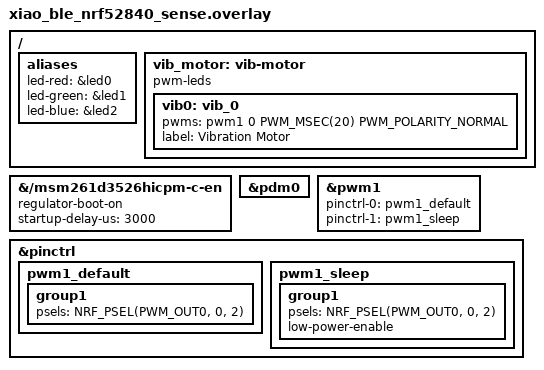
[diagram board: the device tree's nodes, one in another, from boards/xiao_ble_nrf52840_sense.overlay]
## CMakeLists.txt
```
cmake_minimum_required(VERSION 3.20.0)
find_package(Zephyr REQUIRED HINTS $ENV{ZEPHYR_BASE})
project(inside_voice)

target_sources(app PRIVATE
    src/main.c
    src/app/config.c
    src/app/monitor.c
    src/app/data_cache.c
    src/audio/pdm_capture.c
    src/audio/sound_level.c
    src/ble/ble_manager.c
    src/ble/config_service.c
    src/feedback/led.c
    src/feedback/vibration.c
)
```

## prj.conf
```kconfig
# Bluetooth
CONFIG_BT=y
CONFIG_BT_PERIPHERAL=y
CONFIG_BT_DEVICE_NAME="InsideVoice"
CONFIG_BT_DEVICE_APPEARANCE=0
CONFIG_BT_MAX_CONN=1
CONFIG_BT_GATT_DYNAMIC_DB=y

# Audio (PDM/DMIC)
CONFIG_AUDIO=y
CONFIG_AUDIO_DMIC=y

# PWM (vibration motor)
CONFIG_PWM=y

# GPIO (LEDs)
CONFIG_GPIO=y
CONFIG_LED=y

# Persistent settings (NVS)
CONFIG_NVS=y
CONFIG_SETTINGS=y
CONFIG_SETTINGS_NVS=y
CONFIG_FLASH=y
CONFIG_FLASH_MAP=y
CONFIG_FLASH_PAGE_LAYOUT=y

# USB CDC ACM console
CONFIG_USB_DEVICE_STACK=y
CONFIG_USB_CDC_ACM=y
CONFIG_SERIAL=y
CONFIG_CONSOLE=y
CONFIG_UART_CONSOLE=y
CONFIG_UART_LINE_CTRL=y

# Logging
CONFIG_LOG=y
CONFIG_LOG_DEFAULT_LEVEL=3

# Power (enable DC-DC converter for battery life)
CONFIG_BOARD_ENABLE_DCDC=y

# System
CONFIG_HEAP_MEM_POOL_SIZE=4096
CONFIG_MAIN_STACK_SIZE=4096
```

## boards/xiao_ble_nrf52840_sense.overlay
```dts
/ {
	aliases {
		led-red = &led0;
		led-green = &led1;
		led-blue = &led2;
	};

	vib_motor: vib-motor {
		compatible = "pwm-leds";
		status = "okay";

		vib0: vib_0 {
			pwms = <&pwm1 0 PWM_MSEC(20) PWM_POLARITY_NORMAL>;
			label = "Vibration Motor";
		};
	};
};

/* Enable PDM mic power regulator (GPIO P1.10) at boot */
&{/msm261d3526hicpm-c-en} {
	regulator-boot-on;
	startup-delay-us = <3000>;
};

&pdm0 {
	status = "okay";
};

&pwm1 {
	status = "okay";
	pinctrl-0 = <&pwm1_default>;
	pinctrl-1 = <&pwm1_sleep>;
	pinctrl-names = "default", "sleep";
};

&pinctrl {
	pwm1_default: pwm1_default {
		group1 {
			psels = <NRF_PSEL(PWM_OUT0, 0, 2)>;
		};
	};

	pwm1_sleep: pwm1_sleep {
		group1 {
			psels = <NRF_PSEL(PWM_OUT0, 0, 2)>;
			low-power-enable;
		};
	};
};
```

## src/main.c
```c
#include <zephyr/kernel.h>
#include <zephyr/logging/log.h>

#include "app/config.h"
#include "app/monitor.h"
#include "audio/pdm_capture.h"
#include "ble/ble_manager.h"
#include "ble/config_service.h"
#include "feedback/led.h"
#include "feedback/vibration.h"

LOG_MODULE_REGISTER(main, LOG_LEVEL_INF);

int main(void)
{
	int err;

	LOG_INF("InsideVoice firmware starting");

	/* Initialize persistent config (NVS) */
	err = app_config_init();
	if (err) {
		LOG_ERR("Config init failed: %d", err);
		return err;
	}

	/* Initialize audio subsystem */
	err = pdm_capture_init();
	if (err) {
		LOG_ERR("PDM capture init failed: %d", err);
		return err;
	}

	/* Initialize feedback */
	err = led_init();
	if (err) {
		LOG_ERR("LED init failed: %d", err);
		return err;
	}

	err = vibration_init();
	if (err) {
		LOG_ERR("Vibration init failed: %d", err);
		return err;
	}

	/* Initialize BLE */
	err = ble_manager_init();
	if (err) {
		LOG_ERR("BLE init failed: %d", err);
		return err;
	}

	err = config_service_init();
	if (err) {
		LOG_ERR("Config service init failed: %d", err);
		return err;
	}

	/* Start idle LED pattern */
	led_set_pattern(LED_PATTERN_BREATHE_GREEN);

	/* Start monitor thread (reads audio, triggers feedback) */
	err = monitor_start();
	if (err) {
		LOG_ERR("Monitor start failed: %d", err);
		return err;
	}

	LOG_INF("InsideVoice firmware initialized");

	/* main() exits — all work continues in threads */
	return 0;
}
```
